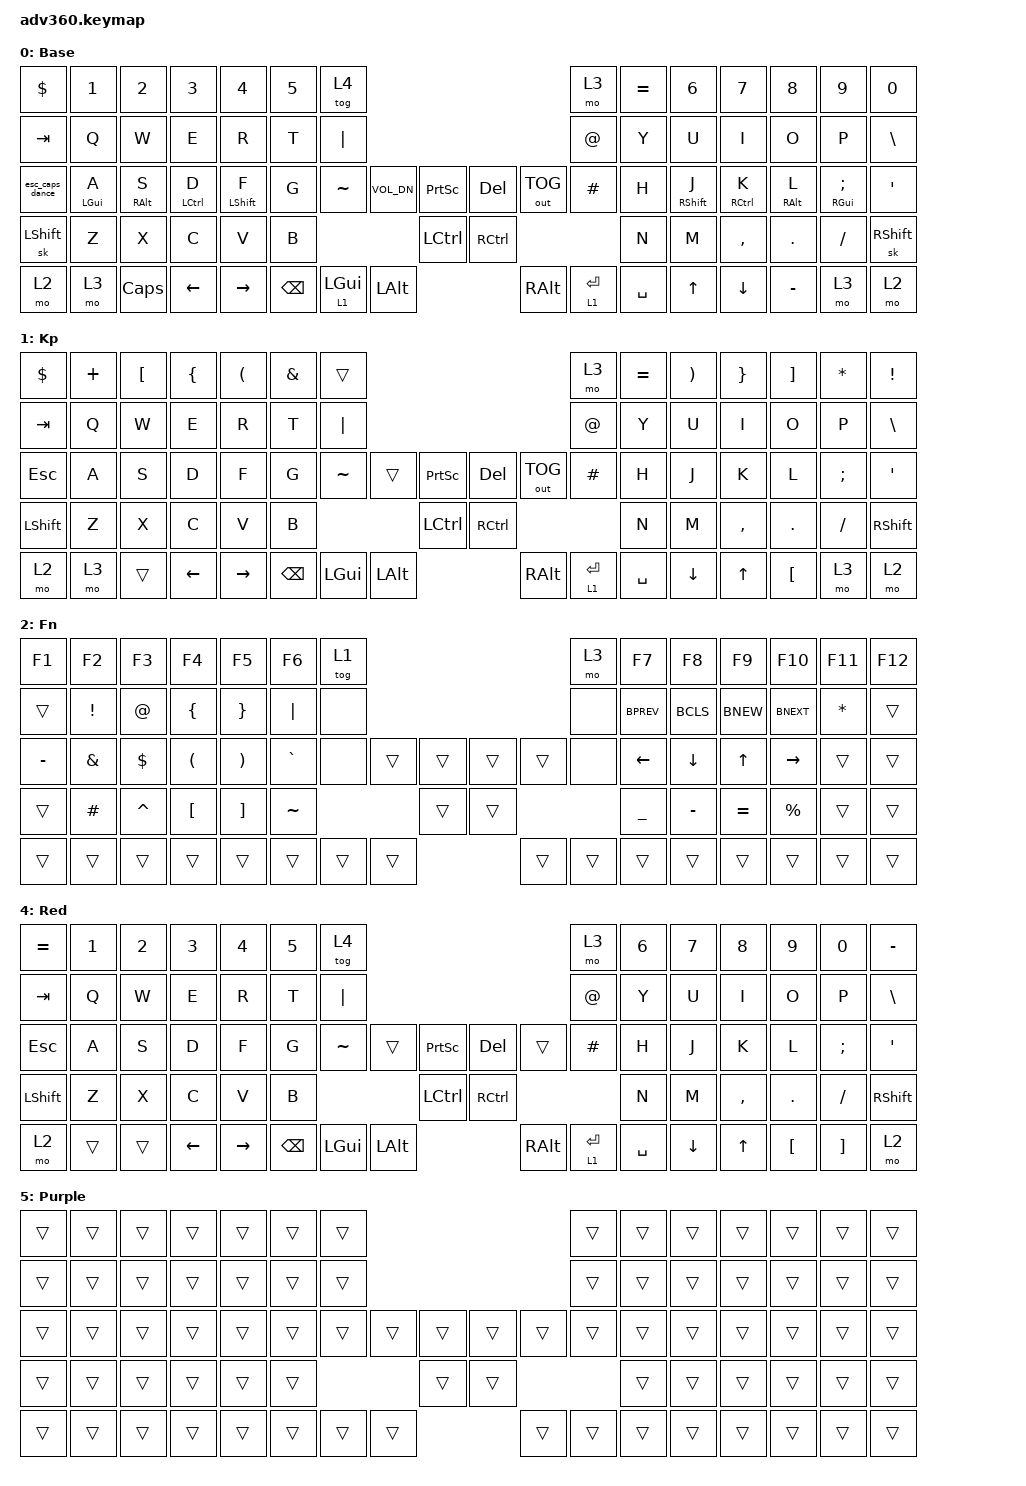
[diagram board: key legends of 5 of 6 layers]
#include <behaviors.dtsi>
#include <dt-bindings/zmk/keys.h>
#include <dt-bindings/zmk/bt.h>
#include <dt-bindings/zmk/rgb.h>
#include <dt-bindings/zmk/stp.h>
#include <dt-bindings/zmk/backlight.h>
#include <dt-bindings/zmk/pointing.h>
#include <dt-bindings/zmk/outputs.h>

&lt {
    quick_tap_ms = <200>;
};

&mt {
    tapping-term-ms = <200>;
    flavor = "tap-preferred";
    retro-tap;
};

&sk {
    release-after-ms = <2000>;
    quick-release;
};

/ {
    #define HYP(key) LS(LC(LA(LG(key))))
    #define HYPER    LS(LC(LA(LGUI)))
    #define MACLOCK  LG(LC(Q))

    #define BNEW  LG(T)
    #define BCLS  LG(W)
    #define BNEXT LG(LA(RIGHT))
    #define BPREV LG(LA(LEFT))
};

/ {
    behaviors {
        #include "macros.dtsi"
        #include "version.dtsi"

        /* Tap-dance para Esc (1 toque) y Caps Lock (doble toque, 130ms para Neovim) */
        esc_caps_dance: esc_caps_dance {
            compatible = "zmk,behavior-tap-dance";
            label = "ESC_CAPS_DANCE";
            #binding-cells = <0>;
            tapping-term-ms = <130>;
            bindings = <&kp ESCAPE>, <&kp CAPSLOCK>;
        };

        /* Homerow mods mano izquierda (posicionales contra misfires) */
        hml: homerow_mods_left {
            compatible = "zmk,behavior-hold-tap";
            label = "HOMEROW_MODS_LEFT";
            #binding-cells = <2>;
            flavor = "balanced";
            tapping-term-ms = <1000>;
            quick-tap-ms = <175>;
            require-prior-idle-ms = <150>;
            hold-trigger-key-positions = <7 8 9 10 11 12 13 21 22 23 24 25 26 27 39 40 41 42 43 44 45 54 55 56 57 58 59 71 72 73 74 75 37 38 53 68 69 70>;
            hold-trigger-on-release;
            bindings = <&kp>, <&kp>;
        };

        /* Homerow mods mano derecha (posicionales contra misfires) */
        hmr: homerow_mods_right {
            compatible = "zmk,behavior-hold-tap";
            label = "HOMEROW_MODS_RIGHT";
            #binding-cells = <2>;
            flavor = "balanced";
            tapping-term-ms = <1000>;
            quick-tap-ms = <175>;
            require-prior-idle-ms = <150>;
            hold-trigger-key-positions = <0 1 2 3 4 5 6 14 15 16 17 18 19 20 28 29 30 31 32 33 34 35 36 46 47 48 49 50 51 52 60 61 62 63 64 65 66 67>;
            hold-trigger-on-release;
            bindings = <&kp>, <&kp>;
        };

        /* Pulgar derecho: Tap = Enter | Hold = Capa 1 (Signos de programación) */
        lt_enter: layer_tap_enter {
            compatible = "zmk,behavior-hold-tap";
            label = "LAYER_TAP_ENTER";
            #binding-cells = <2>;
            flavor = "tap-preferred";
            tapping-term-ms = <200>;
            bindings = <&mo>, <&kp>;
        };

        /* Pulgar izquierdo: Tap = GUI | Hold = Capa 1 (Signos de programación) */
        lt_gui: layer_tap_gui {
            compatible = "zmk,behavior-hold-tap";
            label = "LAYER_TAP_GUI";
            #binding-cells = <2>;
            flavor = "tap-preferred";
            tapping-term-ms = <200>;
            bindings = <&mo>, <&kp>;
        };
    };

    keymap {
        compatible = "zmk,keymap";

        /* Capa 0: Base / Principal (Homerow Mods + Números directos en fila 1) */
        default_layer {
            display-name = "Base";
            bindings = <
                &kp DLLR         &kp N1         &kp N2         &kp N3          &kp N4          &kp N5          &tog 4                                                                          &mo 3        &kp EQUAL     &kp N6          &kp N7          &kp N8         &kp N9           &kp N0
                &kp TAB          &kp Q          &kp W          &kp E           &kp R           &kp T           &kp PIPE                                                                        &kp AT       &kp Y         &kp U           &kp I           &kp O          &kp P            &kp BSLH
                &esc_caps_dance  &hml LGUI A    &hml RALT S    &hml LCTRL D    &hml LSHFT F    &kp G           &kp TILDE              &kp C_VOL_DN &kp PSCRN    &kp DEL    &out OUT_TOG        &kp HASH     &kp H         &hmr RSHFT J    &hmr RCTRL K    &hmr RALT L    &hmr RGUI SEMI   &kp SQT
                &sk LSHFT        &kp Z          &kp X          &kp C           &kp V           &kp B                                               &kp LCTRL    &kp RCTRL                                   &kp N         &kp M           &kp COMMA       &kp DOT        &kp FSLH         &sk RSHFT
                &mo 2            &mo 3          &kp CAPS       &kp LEFT        &kp RIGHT                                &kp BSPC &lt_gui 1 LGUI    &kp LALT     &kp RALT   &lt_enter 1 ENTER &kp SPACE                   &kp UP          &kp DOWN        &kp MINUS      &mo 3            &mo 2
            >;
        };

        /* Capa 1: Kp (Signos de programación al sostener Enter o GUI) */
        keypad {
            display-name = "Kp";
            bindings = <
                &kp DLLR  &kp PLUS  &kp LBKT     &kp LBRC &kp LPAR  &kp AMPS &trans                                                                      &mo 3 &kp EQUAL &kp RPAR  &kp RBRC  &kp RBKT  &kp ASTRK &kp EXCL
                &kp TAB   &kp Q     &kp W        &kp E    &kp R     &kp T    &kp PIPE                                                                    &kp AT &kp Y    &kp U     &kp I     &kp O     &kp P     &kp BSLH
                &kp ESC   &kp A     &kp S        &kp D    &kp F     &kp G    &kp TILDE              &trans       &kp PSCRN &kp DEL   &out OUT_TOG          &kp HASH &kp H   &kp J     &kp K     &kp L     &kp SEMI  &kp SQT
                &kp LSHFT &kp Z     &kp X        &kp C    &kp V     &kp B                                        &kp LCTRL &kp RCTRL                                  &kp N &kp M     &kp COMMA &kp DOT   &kp FSLH  &kp RSHFT
                &mo 2     &mo 3     &trans       &kp LEFT &kp RIGHT                   &kp BSPC &kp LGUI          &kp LALT  &kp RALT  &lt_enter 1 ENTER &kp SPACE             &kp DOWN  &kp UP    &kp LBKT  &mo 3     &mo 2
            >;
        };

        /* Capa 2: Fn */
        fn {
            display-name = "Fn";
            bindings = <
                &kp F1    &kp F2    &kp F3    &kp F4   &kp F5    &kp F6    &tog 1                                                               &mo 3 &kp F7    &kp F8    &kp F9    &kp F10   &kp F11 &kp F12
                &trans    &kp EXCL  &kp AT    &kp LBRC &kp RBRC  &kp PIPE  &none                                                                &none &kp BPREV &kp BCLS  &kp BNEW  &kp BNEXT &kp STAR &trans
                &kp MINUS &kp AMPS  &kp DLLR  &kp LPAR &kp RPAR  &kp GRAVE &none                  &trans &trans &trans &trans                     &none &kp LEFT  &kp DOWN  &kp UP    &kp RIGHT &trans  &trans
                &trans    &kp HASH  &kp CARET &kp LBKT &kp RBKT  &kp TILDE                               &trans &trans                                    &kp UNDER &kp MINUS &kp EQUAL &kp PRCNT &trans  &trans
                &trans    &trans    &trans    &trans   &trans                             &trans &trans &trans &trans &trans &trans                         &trans    &trans    &trans    &trans  &trans
            >;
        };

        /* Capa 3: Mod */
        mod {
            display-name = "Mod";
            bindings = <
                &none          &bt BT_SEL 0 &bt BT_SEL 1 &bt BT_SEL 2 &bt BT_SEL 3 &bt BT_SEL 4 &none                                                                                     &trans       &none &none &none &none &none &none
                &none          &none        &none        &none        &none        &none        &bootloader                                                                               &bootloader  &none &none &none &none &none &none
                &studio_unlock &none        &none        &none        &none        &none        &none                   &none &none &bt BT_CLR &none                         &stp STP_BAT &none        &none &none &none &none &none &none
                &none          &none        &none        &none        &macro_ver   &none                                      &none &none                                                 &none        &none &none &none &none &none &none
                &none          &none        &none        &none        &none                                  &none &none &none &none       &bl BL_TOG &rgb_ug RGB_TOG                               &bl BL_INC &bl BL_DEC &none &none &none
            >;
        };

        /* Capa 4: Red (Capa de Números / Juegos sin Homerow Mods, con signos interiores | ~ @ #) */
        red_layer {
            display-name = "Red";
            bindings = <
                &kp EQUAL &kp N1    &kp N2    &kp N3   &kp N4    &kp N5 &tog 4                                                                      &mo 3 &kp N6    &kp N7    &kp N8    &kp N9    &kp N0   &kp MINUS
                &kp TAB   &kp Q     &kp W     &kp E    &kp R     &kp T  &kp PIPE                                                                    &kp AT &kp Y    &kp U     &kp I     &kp O     &kp P    &kp BSLH
                &kp ESC   &kp A     &kp S     &kp D    &kp F     &kp G  &kp TILDE              &trans &kp PSCRN &kp DEL   &trans                     &kp HASH &kp H   &kp J     &kp K     &kp L     &kp SEMI &kp SQT
                &kp LSHFT &kp Z     &kp X     &kp C    &kp V     &kp B                                &kp LCTRL &kp RCTRL                                  &kp N &kp M     &kp COMMA &kp DOT   &kp FSLH &kp RSHFT
                &mo 2     &trans    &trans    &kp LEFT &kp RIGHT                 &kp BSPC &kp LGUI    &kp LALT  &kp RALT  &lt_enter 1 ENTER &kp SPACE                   &kp DOWN  &kp UP    &kp LBKT  &kp RBKT &mo 2
            >;
        };

        /* Capa 5: Purple */
        purple_layer {
            display-name = "Purple";
            bindings = <
                &trans    &trans    &trans    &trans   &trans    &trans &trans                                                                      &trans &trans    &trans    &trans    &trans    &trans   &trans
                &trans    &trans    &trans    &trans   &trans    &trans &trans                                                                      &trans &trans    &trans    &trans    &trans    &trans   &trans
                &trans    &trans    &trans    &trans   &trans    &trans &trans                 &trans &trans &trans &trans                              &trans &trans    &trans    &trans    &trans    &trans   &trans
                &trans    &trans    &trans    &trans   &trans    &trans                               &trans &trans                                     &trans &trans    &trans    &trans    &trans   &trans
                &trans    &trans    &trans    &trans   &trans                    &trans    &trans     &trans &trans &trans    &trans                            &trans    &trans    &trans    &trans   &trans
            >;
        };

        extra3 {
            display-name = "Cyan";
            status = "reserved";
        };

        extra4 {
            display-name = "Yellow";
            status = "reserved";
        };
    };
};
